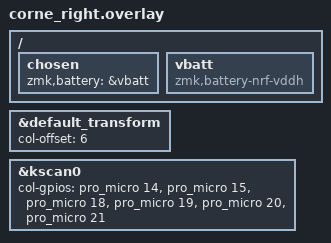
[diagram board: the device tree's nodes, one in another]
#include "corne.dtsi"

&default_transform {
    col-offset = <6>;
};

&kscan0 {
    col-gpios
        = <&pro_micro 14 GPIO_ACTIVE_HIGH> // Col 6
        , <&pro_micro 15 GPIO_ACTIVE_HIGH> // Col 7
        , <&pro_micro 18 GPIO_ACTIVE_HIGH> // Col 8
        , <&pro_micro 19 GPIO_ACTIVE_HIGH> // Col 9
        , <&pro_micro 20 GPIO_ACTIVE_HIGH> // Col 10
        , <&pro_micro 21 GPIO_ACTIVE_HIGH> // Col 11
        ;
};

/ {
    chosen {
        zmk,battery = &vbatt;
    };

    vbatt: vbatt {
        compatible = "zmk,battery-nrf-vddh";
    };
};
